AUTOSAR XML (schema 4-2-2)
package /ASWC
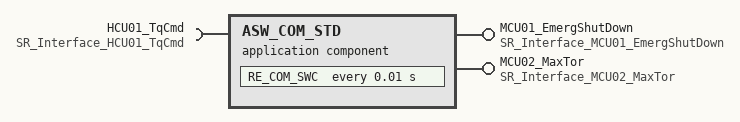
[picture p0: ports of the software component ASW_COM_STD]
  application sw component type ASW_COM_STD
    provide port MCU01_EmergShutDown: provided-interface=SR_Interface_MCU01_EmergShutDown
    provide port MCU02_MaxTor: provided-interface=SR_Interface_MCU02_MaxTor
    require port HCU01_TqCmd: nonqueued-receiver-com-spec{data-element=DE_TqCmd, alive-timeout=0.3}, required-interface=SR_Interface_HCU01_TqCmd
    behavior IB_ASW_COM_STD
      timing event TE_RE_COM_SWC_10ms: start-on-event=RE_COM_SWC, period=0.01
      runnable RE_COM_SWC
        data read access DRA_HCU01_TqCmd: accessed-variable=HCU01_TqCmd.DE_TqCmd
        data write access DWA_MCU01_EmergShutDown: accessed-variable=MCU01_EmergShutDown.DE_EmergShutDown
        data write access DWA_MCU02_MaxTor: accessed-variable=MCU02_MaxTor.DE_MaxTor
package /COM_Interface
  sender receiver interface SR_Interface_MCU01_EmergShutDown
    data DE_EmergShutDown: type=dt_Boolean
  sender receiver interface SR_Interface_MCU02_MaxTor
    data DE_MaxTor: type=dt_Float
  sender receiver interface SR_Interface_HCU01_TqCmd
    data DE_TqCmd: type=dt_Float
package /DataTypes
  impl type dt_Boolean: category=VALUE, base-type=boolean
  impl type dt_Float: category=VALUE, base-type=float32
